# Cortex_M52 register map
Vendor: Arm Ltd.; Series: ARMv8.1-M Mainline; File version: 1.0.0
CPU: other r0p0, little endian, MPU, FPU, double-precision FPU, DSP, 8 interrupt priority bits
Registers are 32-bit, read-write, reset 0x0 unless marked. A register's access mark holds for its fields unless they carry their own. Offsets are from the block's base; [hi:lo] are bit positions; 'fields as' and 'values as' point back to an identical list.

## DIB — Debug Identification Block (ARMv8-M): software lock, debug authentication status and the SCS CoreSight architecture and type IDs.
Base 0xE000EFB0
Same registers: DIB_NS 0xE002EFB0
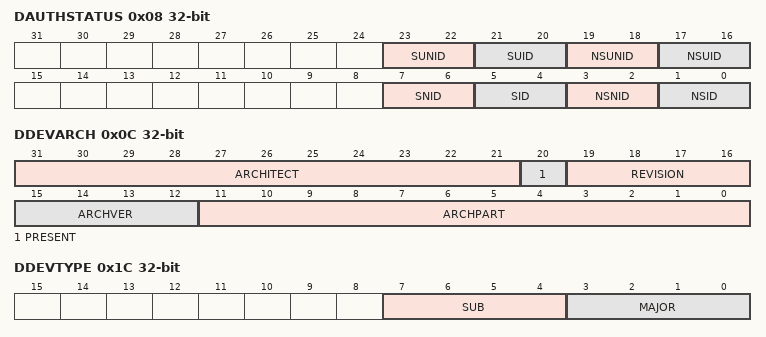
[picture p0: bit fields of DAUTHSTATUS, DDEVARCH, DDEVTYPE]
0x08 DAUTHSTATUS ro — Debug Authentication Status Register: which kinds of debug (invasive/non-invasive, Secure/Non-secure, unprivileged) are currently enabled.
  [23:22] SUNID — Secure unprivileged non-invasive debug: 2 = disabled, 3 = enabled.
  [21:20] SUID — Secure unprivileged invasive debug: 2 = disabled, 3 = enabled.
  [19:18] NSUNID — Non-secure unprivileged non-invasive debug: 2 = disabled, 3 = enabled.
  [17:16] NSUID — Non-secure unprivileged invasive debug (ARMv8.1-M UDE): 2 = disabled, 3 = enabled.
  [7:6] SNID — Secure non-invasive debug: 0 = not implemented, 2 = disabled, 3 = enabled.
  [5:4] SID — Secure invasive debug: 0 = not implemented, 2 = disabled, 3 = enabled.
  [3:2] NSNID — Non-secure non-invasive debug (trace): 0 = not implemented, 2 = disabled, 3 = enabled.
  [1:0] NSID — Non-secure invasive debug: 0 = not implemented, 2 = disabled, 3 = enabled.
0x0C DDEVARCH ro — SCS Device Architecture Register: CoreSight ARCHID of the debug architecture (0x2A04 = ARMv8-M debug) and the architect (Arm, 0x23B).
  [31:21] ARCHITECT — JEP106 code of the architect: 0x23B = Arm.
  [20] PRESENT — 1 = DDEVARCH is present and its contents are valid.
  [19:16] REVISION — Architecture revision.
  [15:12] ARCHVER — Architecture version: 2 = ARMv8-M debug architecture.
  [11:0] ARCHPART — Architecture part: 0xA04 = M-profile system control space (with ARCHVER 2 -> ARCHID 0x2A04, ARMv8-M debug).
0x1C DDEVTYPE ro — SCS Device Type Register: CoreSight major/sub type of the SCS (0x00 = processor system control).
  [7:4] SUB — Sub type: 0 for the SCS.
  [3:0] MAJOR — Major type: 0 = miscellaneous / processor system control.

## ERRBNK — Error Bank: records the location of ECC errors detected in the instruction cache, data cache and (Cortex-M55/M85) TCM RAMs, so software can scrub the location and diagnose failing RAM.
Base 0xE001E100
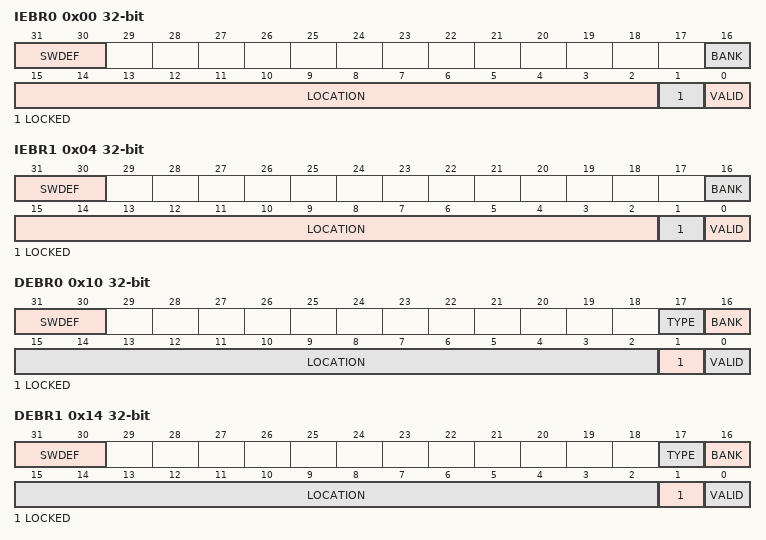
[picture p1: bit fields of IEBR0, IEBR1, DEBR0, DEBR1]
0x00 IEBR0 — Instruction Cache Error Bank Register 0: the first recorded I-cache ECC error.
  [31:30] SWDEF — Software-defined bits (not used by hardware).
  [16] BANK — RAM bank of the error.
  [15:2] LOCATION — Location of the error inside the I-cache (set/way/word encoding, see the TRM).
  [1] LOCKED — Locked: a further error occurred while this entry was valid; the entry keeps the first error until cleared.
  [0] VALID — Entry valid: an error has been recorded. Clear it after scrubbing the location.
0x04 IEBR1 — Instruction Cache Error Bank Register 1: the second recorded I-cache ECC error.
  fields as IEBR0
0x10 DEBR0 — Data Cache Error Bank Register 0: the first recorded D-cache ECC error.
  [31:30] SWDEF — Software-defined bits (not used by hardware).
  [17] TYPE — Error type: 0 = data RAM, 1 = tag/dirty RAM.
  [16] BANK — RAM bank of the error.
  [15:2] LOCATION — Location of the error inside the D-cache (set/way/word encoding, see the TRM).
  [1] LOCKED — Locked: a further error occurred while this entry was valid; the entry keeps the first error until cleared.
  [0] VALID — Entry valid: an error has been recorded.
0x14 DEBR1 — Data Cache Error Bank Register 1: the second recorded D-cache ECC error.
  fields as DEBR0
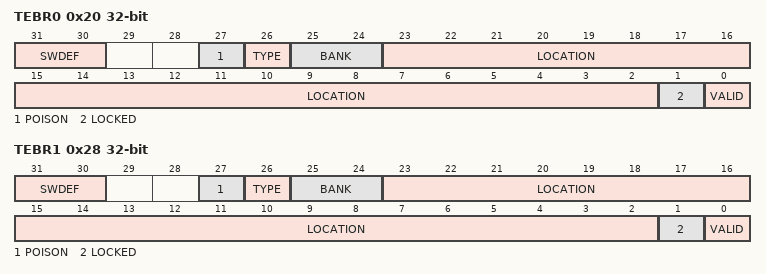
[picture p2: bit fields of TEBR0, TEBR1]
0x20 TEBR0 — TCM Error Bank Register 0: the first recorded TCM ECC error.
  [31:30] SWDEF — Software-defined bits (not used by hardware).
  [27] POISON — 1 = the location was poisoned (its data marked invalid) after an uncorrectable error.
  [26] TYPE — Error type: 0 = correctable (single-bit), 1 = uncorrectable (double-bit).
  [25:24] BANK — TCM bank: which of the ITCM/DTCM RAM banks the error was in.
  [23:2] LOCATION — Word address of the error within the TCM.
  [1] LOCKED — Locked: a further error occurred while this entry was valid.
  [0] VALID — Entry valid: an error has been recorded.
0x24 TEBRDATA0 ro — Storage for corrected data that is associated with an error.
0x28 TEBR1 — TCM Error Bank Register 1: the second recorded TCM ECC error.
  fields as TEBR0
0x2C TEBRDATA1 ro — Storage for corrected data that is associated with an error.
